# vpac_targetdb register map
Vendor: Texas Instruments
Registers are 32-bit, read-write, no defined reset value unless marked. A register's access mark holds for its fields unless they carry their own. Offsets are as the file gives them; [hi:lo] are bit positions; {n}, {i} and the like mark numbered series; 'fields as' and 'values as' point back to an identical list.

## VPAC (part 7 of 8) — Vision Pre-Processing Accelerator (VPAC)
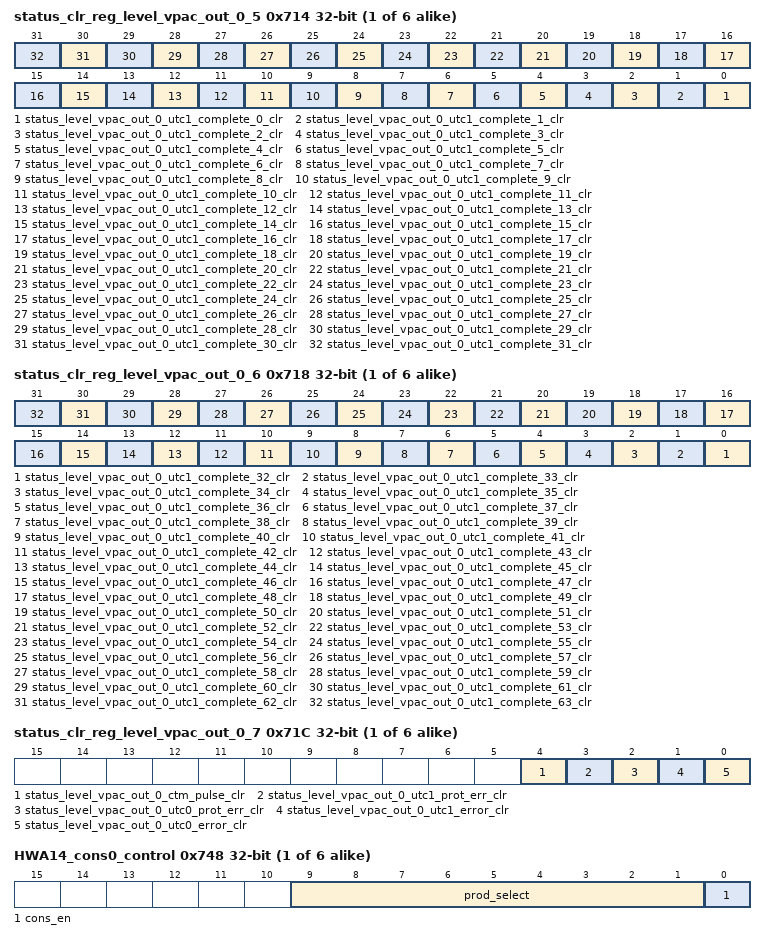
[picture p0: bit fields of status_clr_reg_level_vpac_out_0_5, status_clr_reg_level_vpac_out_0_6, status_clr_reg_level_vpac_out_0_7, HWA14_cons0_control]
{0x714+0x20*i} status_clr_reg_level_vpac_out_{i}_5 (i=0..5) — Status Clear Register {8i+5}
  [n] status_level_vpac_out_{i}_utc1_complete_{n}_clr (n=0..31) — Status ,write 1 to clear, for level_vpac_out_{i}_en_utc1_complete_{n}
{0x718+0x20*i} status_clr_reg_level_vpac_out_{i}_6 (i=0..5) — Status Clear Register {8i+6}
  [n-32] status_level_vpac_out_{i}_utc1_complete_{n}_clr (n=32..63) — Status ,write 1 to clear, for level_vpac_out_{i}_en_utc1_complete_{n}
{0x71C+0x20*i} status_clr_reg_level_vpac_out_{i}_7 (i=0..5) — Status Clear Register {8i+7}
  [4] status_level_vpac_out_{i}_ctm_pulse_clr — Status ,write 1 to clear, for level_vpac_out_{i}_en_ctm_pulse
  [3] status_level_vpac_out_{i}_utc1_prot_err_clr — Status ,write 1 to clear, for level_vpac_out_{i}_en_utc1_prot_err
  [2] status_level_vpac_out_{i}_utc0_prot_err_clr — Status ,write 1 to clear, for level_vpac_out_{i}_en_utc0_prot_err
  [1] status_level_vpac_out_{i}_utc1_error_clr — Status ,write 1 to clear, for level_vpac_out_{i}_en_utc1_error
  [0] status_level_vpac_out_{i}_utc0_error_clr — Status ,write 1 to clear, for level_vpac_out_{i}_en_utc0_error
{0x198+0x68*i} HWA{i}_cons0_control (i=14..19) — Controlling consumer socket 0 for HWA{i}
  [9:1] prod_select — producer select for HWA{i} cons socket 0
  [0] cons_en — '1' -> Consumer socket 0 enable , '0' Disable
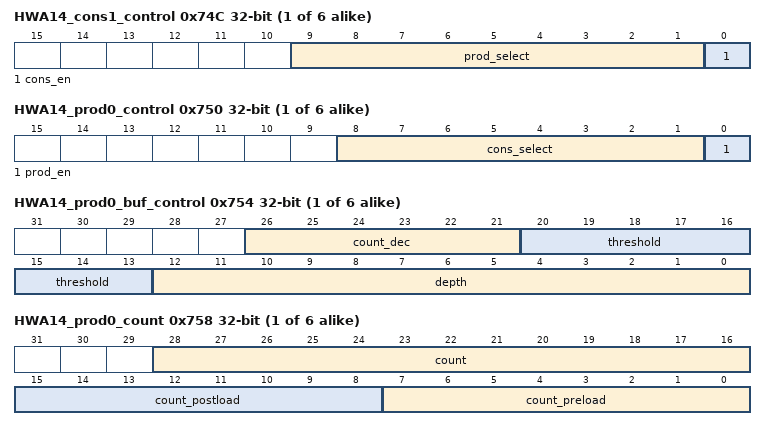
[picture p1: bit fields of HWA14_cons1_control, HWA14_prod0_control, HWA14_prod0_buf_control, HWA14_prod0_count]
{0x19C+0x68*i} HWA{i}_cons1_control (i=14..19) — Controlling consumer socket 1 for HWA{i}
  [9:1] prod_select — producer select for HWA{i} cons socket 1
  [0] cons_en — '1' -> Consumer socket 1 enable , '0' Disable
{0x1A0+0x68*i} HWA{i}_prod0_control (i=14..19) — Controlling producer socket0 for HWA{i}
  [8:1] cons_select — consumer select for HWA{i} prod socket 0. Used in decrementing count of producer buffer
  [0] prod_en — '1' -> Producer socket 0 enable , '0' Disable
{0x1A4+0x68*i} HWA{i}_prod0_buf_control (i=14..19) — Controlling producer socket0 buffer for HWA{i}
  [26:21] count_dec — Count decrement value for prod count
  [20:13] threshold — Count threshold to generate pend for consumer
  [12:0] depth — Maximum number of producer buffer count
{0x1A8+0x68*i} HWA{i}_prod0_count access per field (i=14..19) — Defining count values for pre/post load for generating pend by HWA{i} prod0
  [28:16] count ro — current count value
  [15:8] count_postload rw — count postload after producer max thread count reached
  [7:0] count_preload rw — count preload after scheduler start/init
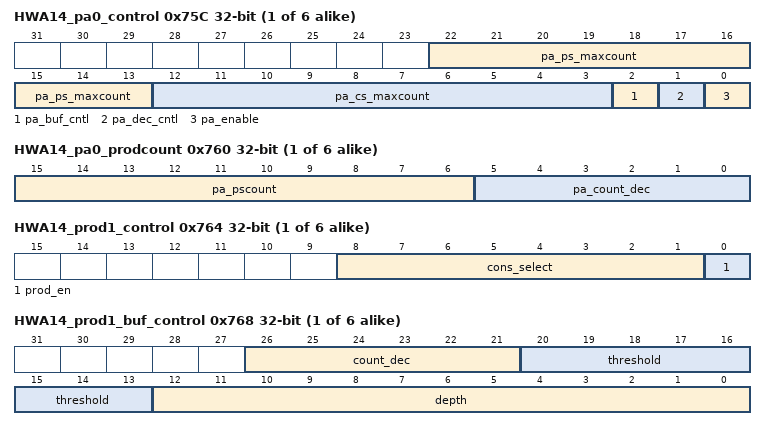
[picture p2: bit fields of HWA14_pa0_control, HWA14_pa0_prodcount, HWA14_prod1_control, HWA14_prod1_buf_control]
{0x1AC+0x68*i} HWA{i}_pa0_control (i=14..19) — control register to manage pattern adapter on HWA{i} prod socket0
  [22:13] pa_ps_maxcount — destination count for pattern adaptation (N), M --> N
  [12:3] pa_cs_maxcount — source count for pattern adaptation (M), M --> N
  [2] pa_buf_cntl — '1' -> Apply threshold, count_preload and count_postload on pattern adapter count (use this only when pa_enable='1') '0' -> Apply threshold, count_preload and count_postload on prod count (same behavior as if no pattern adapter. Note when pa_enable='1' and pa_buf_cntl='0' threshold is not used and ignored)
  [1] pa_dec_cntl — '1' -> post pattern adaptation, decrement ps count by count_dec , '0' -> post pattern adaptation, decrement ps count by pa_cs_maxcount
  [0] pa_enable — '1' -> pa enable, '0' -> disable
{0x1B0+0x68*i} HWA{i}_pa0_prodcount access per field (i=14..19) — count values for HWA{i} prod socket0
  [15:6] pa_pscount ro — current count value of pa prod count
  [5:0] pa_count_dec rw — Decrement count value of pa_prod_count after pattern adapter prod count reaches threshold
{0x1B4+0x68*i} HWA{i}_prod1_control (i=14..19) — Controlling producer socket1 for HWA{i}
  [8:1] cons_select — consumer select for HWA{i} prod socket 1. Used in decrementing count of producer buffer
  [0] prod_en — '1' -> Producer socket 0 enable , '0' Disable
{0x1B8+0x68*i} HWA{i}_prod1_buf_control (i=14..19) — Controlling producer socket1 buffer for HWA{i}
  fields as HWA14_prod0_buf_control
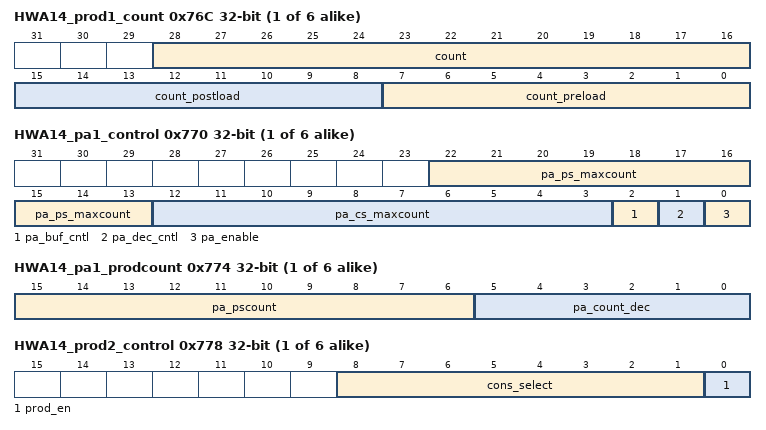
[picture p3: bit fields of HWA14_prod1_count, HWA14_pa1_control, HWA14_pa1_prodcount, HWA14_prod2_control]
{0x1BC+0x68*i} HWA{i}_prod1_count access per field (i=14..19) — Defining count values for pre/post load for generating pend by HWA{i} prod1
  fields as HWA14_prod0_count
{0x1C0+0x68*i} HWA{i}_pa1_control (i=14..19) — control register to manage pattern adapter on HWA{i} prod socket1
  fields as HWA14_pa0_control
{0x1C4+0x68*i} HWA{i}_pa1_prodcount access per field (i=14..19) — count values for HWA{i} prod socket1
  fields as HWA14_pa0_prodcount
{0x1C8+0x68*i} HWA{i}_prod2_control (i=14..19) — Controlling producer socket2 for HWA{i}
  [8:1] cons_select — consumer select for HWA{i} prod socket 2. Used in decrementing count of producer buffer
  [0] prod_en — '1' -> Producer socket 0 enable , '0' Disable
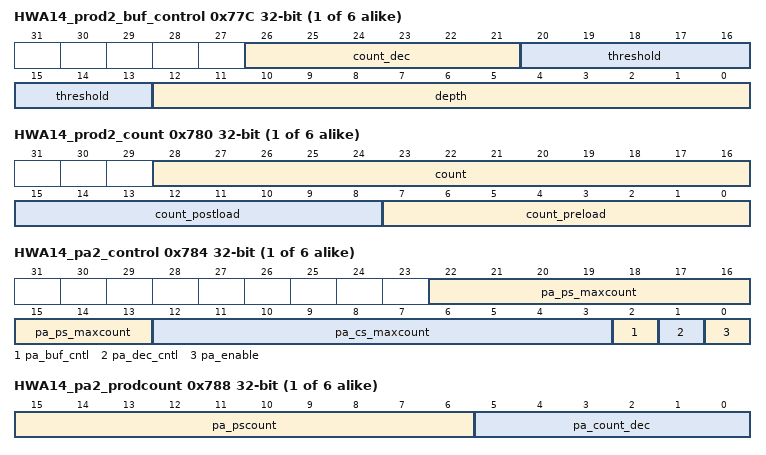
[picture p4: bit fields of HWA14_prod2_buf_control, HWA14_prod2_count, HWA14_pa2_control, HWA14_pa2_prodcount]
{0x1CC+0x68*i} HWA{i}_prod2_buf_control (i=14..19) — Controlling producer socket2 buffer for HWA{i}
  fields as HWA14_prod0_buf_control
{0x1D0+0x68*i} HWA{i}_prod2_count access per field (i=14..19) — Defining count values for pre/post load for generating pend by HWA{i} prod2
  fields as HWA14_prod0_count
{0x1D4+0x68*i} HWA{i}_pa2_control (i=14..19) — control register to manage pattern adapter on HWA{i} prod socket2
  fields as HWA14_pa0_control
{0x1D8+0x68*i} HWA{i}_pa2_prodcount access per field (i=14..19) — count values for HWA{i} prod socket2
  fields as HWA14_pa0_prodcount
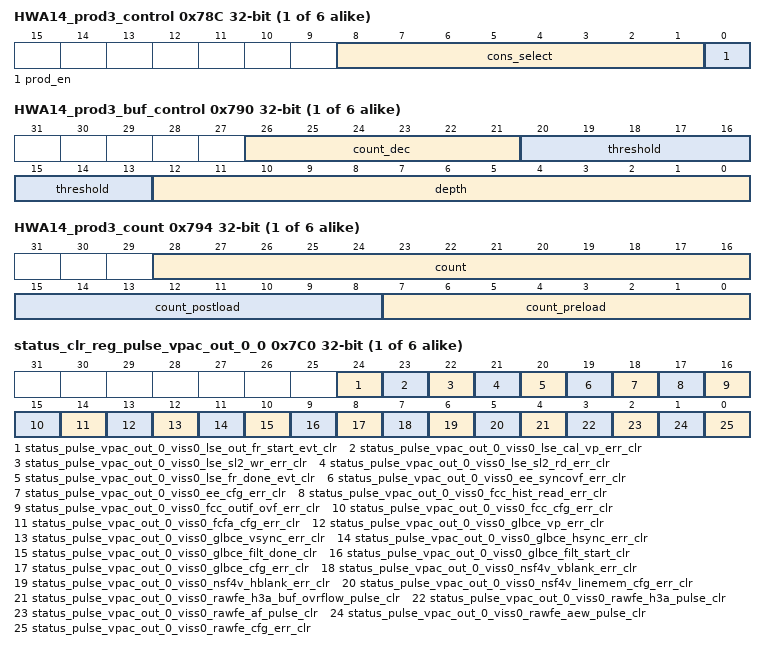
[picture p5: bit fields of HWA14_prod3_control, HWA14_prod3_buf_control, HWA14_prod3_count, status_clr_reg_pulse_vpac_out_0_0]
{0x1DC+0x68*i} HWA{i}_prod3_control (i=14..19) — Controlling producer socket3 for HWA{i}
  [8:1] cons_select — consumer select for HWA{i} prod socket 3. Used in decrementing count of producer buffer
  [0] prod_en — '1' -> Producer socket 0 enable , '0' Disable
{0x1E0+0x68*i} HWA{i}_prod3_buf_control (i=14..19) — Controlling producer socket3 buffer for HWA{i}
  fields as HWA14_prod0_buf_control
{0x1E4+0x68*i} HWA{i}_prod3_count access per field (i=14..19) — Defining count values for pre/post load for generating pend by HWA{i} prod3
  fields as HWA14_prod0_count
{0x7C0+0x20*i} status_clr_reg_pulse_vpac_out_{i}_0 (i=0..5) — Status Clear Register {8i+48}
  [24] status_pulse_vpac_out_{i}_viss0_lse_out_fr_start_evt_clr — Status ,write 1 to clear, for pulse_vpac_out_{i}_en_viss0_lse_out_fr_start_evt
  [23] status_pulse_vpac_out_{i}_viss0_lse_cal_vp_err_clr — Status ,write 1 to clear, for pulse_vpac_out_{i}_en_viss0_lse_cal_vp_err
  [22] status_pulse_vpac_out_{i}_viss0_lse_sl2_wr_err_clr — Status ,write 1 to clear, for pulse_vpac_out_{i}_en_viss0_lse_sl2_wr_err
  [21] status_pulse_vpac_out_{i}_viss0_lse_sl2_rd_err_clr — Status ,write 1 to clear, for pulse_vpac_out_{i}_en_viss0_lse_sl2_rd_err
  [20] status_pulse_vpac_out_{i}_viss0_lse_fr_done_evt_clr — Status ,write 1 to clear, for pulse_vpac_out_{i}_en_viss0_lse_fr_done_evt
  [19] status_pulse_vpac_out_{i}_viss0_ee_syncovf_err_clr — Status ,write 1 to clear, for pulse_vpac_out_{i}_en_viss0_ee_syncovf_err
  [18] status_pulse_vpac_out_{i}_viss0_ee_cfg_err_clr — Status ,write 1 to clear, for pulse_vpac_out_{i}_en_viss0_ee_cfg_err
  [17] status_pulse_vpac_out_{i}_viss0_fcc_hist_read_err_clr — Status ,write 1 to clear, for pulse_vpac_out_{i}_en_viss0_fcc_hist_read_err
  [16] status_pulse_vpac_out_{i}_viss0_fcc_outif_ovf_err_clr — Status ,write 1 to clear, for pulse_vpac_out_{i}_en_viss0_fcc_outif_ovf_err
  [15] status_pulse_vpac_out_{i}_viss0_fcc_cfg_err_clr — Status ,write 1 to clear, for pulse_vpac_out_{i}_en_viss0_fcc_cfg_err
  [14] status_pulse_vpac_out_{i}_viss0_fcfa_cfg_err_clr — Status ,write 1 to clear, for pulse_vpac_out_{i}_en_viss0_fcfa_cfg_err
  [13] status_pulse_vpac_out_{i}_viss0_glbce_vp_err_clr — Status ,write 1 to clear, for pulse_vpac_out_{i}_en_viss0_glbce_vp_err
  [12] status_pulse_vpac_out_{i}_viss0_glbce_vsync_err_clr — Status ,write 1 to clear, for pulse_vpac_out_{i}_en_viss0_glbce_vsync_err
  [11] status_pulse_vpac_out_{i}_viss0_glbce_hsync_err_clr — Status ,write 1 to clear, for pulse_vpac_out_{i}_en_viss0_glbce_hsync_err
  [10] status_pulse_vpac_out_{i}_viss0_glbce_filt_done_clr — Status ,write 1 to clear, for pulse_vpac_out_{i}_en_viss0_glbce_filt_done
  [9] status_pulse_vpac_out_{i}_viss0_glbce_filt_start_clr — Status ,write 1 to clear, for pulse_vpac_out_{i}_en_viss0_glbce_filt_start
  [8] status_pulse_vpac_out_{i}_viss0_glbce_cfg_err_clr — Status ,write 1 to clear, for pulse_vpac_out_{i}_en_viss0_glbce_cfg_err
  [7] status_pulse_vpac_out_{i}_viss0_nsf4v_vblank_err_clr — Status ,write 1 to clear, for pulse_vpac_out_{i}_en_viss0_nsf4v_vblank_err
  [6] status_pulse_vpac_out_{i}_viss0_nsf4v_hblank_err_clr — Status ,write 1 to clear, for pulse_vpac_out_{i}_en_viss0_nsf4v_hblank_err
  [5] status_pulse_vpac_out_{i}_viss0_nsf4v_linemem_cfg_err_clr — Status ,write 1 to clear, for pulse_vpac_out_{i}_en_viss0_nsf4v_linemem_cfg_err
  [4] status_pulse_vpac_out_{i}_viss0_rawfe_h3a_buf_ovrflow_pulse_clr — Status ,write 1 to clear, for pulse_vpac_out_{i}_en_viss0_rawfe_h3a_buf_ovrflow_pulse
  [3] status_pulse_vpac_out_{i}_viss0_rawfe_h3a_pulse_clr — Status ,write 1 to clear, for pulse_vpac_out_{i}_en_viss0_rawfe_h3a_pulse
  [2] status_pulse_vpac_out_{i}_viss0_rawfe_af_pulse_clr — Status ,write 1 to clear, for pulse_vpac_out_{i}_en_viss0_rawfe_af_pulse
  [1] status_pulse_vpac_out_{i}_viss0_rawfe_aew_pulse_clr — Status ,write 1 to clear, for pulse_vpac_out_{i}_en_viss0_rawfe_aew_pulse
  [0] status_pulse_vpac_out_{i}_viss0_rawfe_cfg_err_clr — Status ,write 1 to clear, for pulse_vpac_out_{i}_en_viss0_rawfe_cfg_err
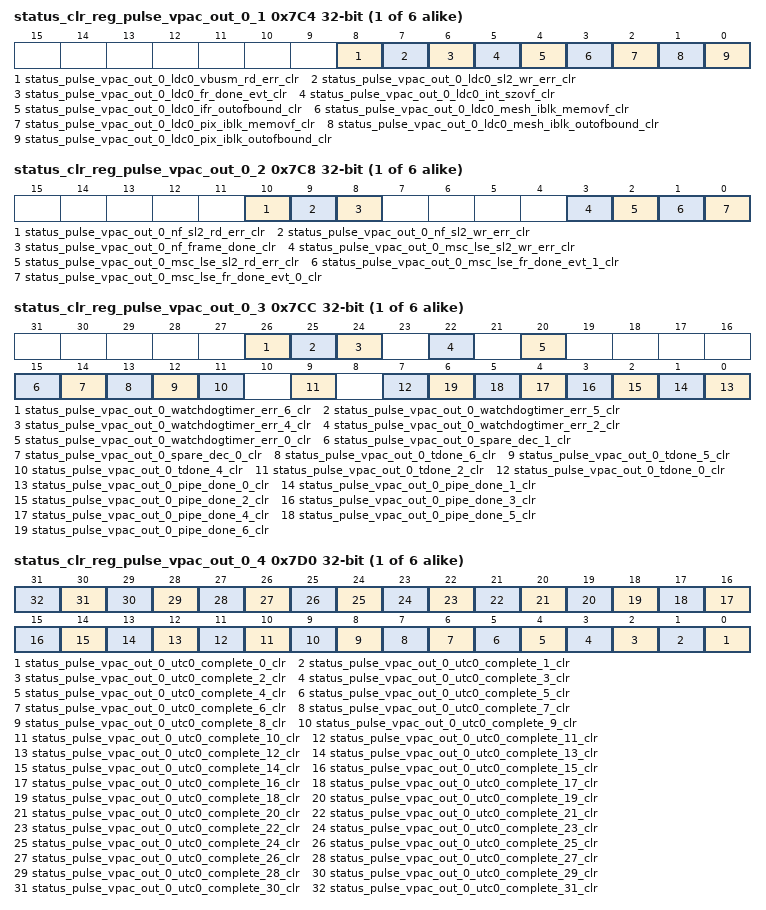
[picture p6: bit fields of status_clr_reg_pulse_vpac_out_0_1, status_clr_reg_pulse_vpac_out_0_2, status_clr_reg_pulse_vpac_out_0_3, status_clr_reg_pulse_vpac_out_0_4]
{0x7C4+0x20*i} status_clr_reg_pulse_vpac_out_{i}_1 (i=0..5) — Status Clear Register {8i+49}
  [8] status_pulse_vpac_out_{i}_ldc0_vbusm_rd_err_clr — Status ,write 1 to clear, for pulse_vpac_out_{i}_en_ldc0_vbusm_rd_err
  [7] status_pulse_vpac_out_{i}_ldc0_sl2_wr_err_clr — Status ,write 1 to clear, for pulse_vpac_out_{i}_en_ldc0_sl2_wr_err
  [6] status_pulse_vpac_out_{i}_ldc0_fr_done_evt_clr — Status ,write 1 to clear, for pulse_vpac_out_{i}_en_ldc0_fr_done_evt
  [5] status_pulse_vpac_out_{i}_ldc0_int_szovf_clr — Status ,write 1 to clear, for pulse_vpac_out_{i}_en_ldc0_int_szovf
  [4] status_pulse_vpac_out_{i}_ldc0_ifr_outofbound_clr — Status ,write 1 to clear, for pulse_vpac_out_{i}_en_ldc0_ifr_outofbound
  [3] status_pulse_vpac_out_{i}_ldc0_mesh_iblk_memovf_clr — Status ,write 1 to clear, for pulse_vpac_out_{i}_en_ldc0_mesh_iblk_memovf
  [2] status_pulse_vpac_out_{i}_ldc0_pix_iblk_memovf_clr — Status ,write 1 to clear, for pulse_vpac_out_{i}_en_ldc0_pix_iblk_memovf
  [1] status_pulse_vpac_out_{i}_ldc0_mesh_iblk_outofbound_clr — Status ,write 1 to clear, for pulse_vpac_out_{i}_en_ldc0_mesh_iblk_outofbound
  [0] status_pulse_vpac_out_{i}_ldc0_pix_iblk_outofbound_clr — Status ,write 1 to clear, for pulse_vpac_out_{i}_en_ldc0_pix_iblk_outofbound
{0x7C8+0x20*i} status_clr_reg_pulse_vpac_out_{i}_2 (i=0..5) — Status Clear Register {8i+50}
  [10] status_pulse_vpac_out_{i}_nf_sl2_rd_err_clr — Status ,write 1 to clear, for pulse_vpac_out_{i}_en_nf_sl2_rd_err
  [9] status_pulse_vpac_out_{i}_nf_sl2_wr_err_clr — Status ,write 1 to clear, for pulse_vpac_out_{i}_en_nf_sl2_wr_err
  [8] status_pulse_vpac_out_{i}_nf_frame_done_clr — Status ,write 1 to clear, for pulse_vpac_out_{i}_en_nf_frame_done
  [3] status_pulse_vpac_out_{i}_msc_lse_sl2_wr_err_clr — Status ,write 1 to clear, for pulse_vpac_out_{i}_en_msc_lse_sl2_wr_err
  [2] status_pulse_vpac_out_{i}_msc_lse_sl2_rd_err_clr — Status ,write 1 to clear, for pulse_vpac_out_{i}_en_msc_lse_sl2_rd_err
  [1] status_pulse_vpac_out_{i}_msc_lse_fr_done_evt_1_clr — Status ,write 1 to clear, for pulse_vpac_out_{i}_en_msc_lse_fr_done_evt_1
  [0] status_pulse_vpac_out_{i}_msc_lse_fr_done_evt_0_clr — Status ,write 1 to clear, for pulse_vpac_out_{i}_en_msc_lse_fr_done_evt_0
{0x7CC+0x20*i} status_clr_reg_pulse_vpac_out_{i}_3 (i=0..5) — Status Clear Register {8i+51}
  [26] status_pulse_vpac_out_{i}_watchdogtimer_err_6_clr — Status ,write 1 to clear, for pulse_vpac_out_{i}_en_watchdogtimer_err_6
  [25] status_pulse_vpac_out_{i}_watchdogtimer_err_5_clr — Status ,write 1 to clear, for pulse_vpac_out_{i}_en_watchdogtimer_err_5
  [24] status_pulse_vpac_out_{i}_watchdogtimer_err_4_clr — Status ,write 1 to clear, for pulse_vpac_out_{i}_en_watchdogtimer_err_4
  [22] status_pulse_vpac_out_{i}_watchdogtimer_err_2_clr — Status ,write 1 to clear, for pulse_vpac_out_{i}_en_watchdogtimer_err_2
  [20] status_pulse_vpac_out_{i}_watchdogtimer_err_0_clr — Status ,write 1 to clear, for pulse_vpac_out_{i}_en_watchdogtimer_err_0
  [15] status_pulse_vpac_out_{i}_spare_dec_1_clr — Status ,write 1 to clear, for pulse_vpac_out_{i}_en_spare_dec_1
  [14] status_pulse_vpac_out_{i}_spare_dec_0_clr — Status ,write 1 to clear, for pulse_vpac_out_{i}_en_spare_dec_0
  [13] status_pulse_vpac_out_{i}_tdone_6_clr — Status ,write 1 to clear, for pulse_vpac_out_{i}_en_tdone_6
  [12] status_pulse_vpac_out_{i}_tdone_5_clr — Status ,write 1 to clear, for pulse_vpac_out_{i}_en_tdone_5
  [11] status_pulse_vpac_out_{i}_tdone_4_clr — Status ,write 1 to clear, for pulse_vpac_out_{i}_en_tdone_4
  [9] status_pulse_vpac_out_{i}_tdone_2_clr — Status ,write 1 to clear, for pulse_vpac_out_{i}_en_tdone_2
  [7] status_pulse_vpac_out_{i}_tdone_0_clr — Status ,write 1 to clear, for pulse_vpac_out_{i}_en_tdone_0
  [n] status_pulse_vpac_out_{i}_pipe_done_{n}_clr (n=0..6) — Status ,write 1 to clear, for pulse_vpac_out_{i}_en_pipe_done_{n}
{0x7D0+0x20*i} status_clr_reg_pulse_vpac_out_{i}_4 (i=0..5) — Status Clear Register {8i+52}
  [n] status_pulse_vpac_out_{i}_utc0_complete_{n}_clr (n=0..31) — Status ,write 1 to clear, for pulse_vpac_out_{i}_en_utc0_complete_{n}
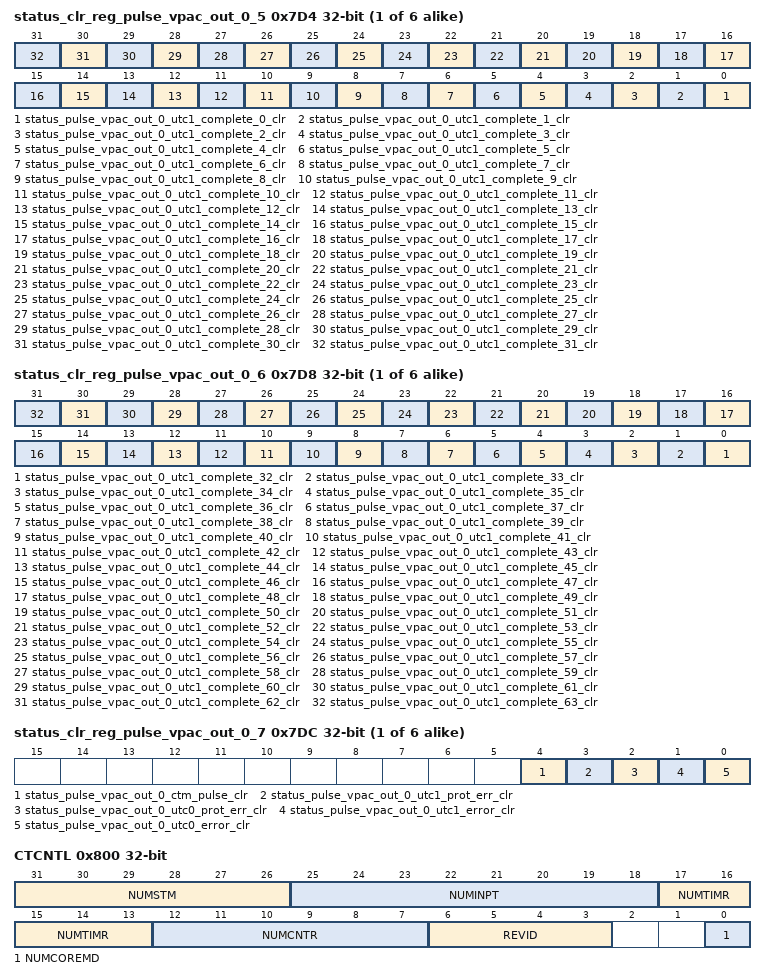
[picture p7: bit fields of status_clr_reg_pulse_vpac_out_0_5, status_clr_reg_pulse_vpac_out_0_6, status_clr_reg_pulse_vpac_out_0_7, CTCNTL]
{0x7D4+0x20*i} status_clr_reg_pulse_vpac_out_{i}_5 (i=0..5) — Status Clear Register {8i+53}
  [n] status_pulse_vpac_out_{i}_utc1_complete_{n}_clr (n=0..31) — Status ,write 1 to clear, for pulse_vpac_out_{i}_en_utc1_complete_{n}
{0x7D8+0x20*i} status_clr_reg_pulse_vpac_out_{i}_6 (i=0..5) — Status Clear Register {8i+54}
  [n-32] status_pulse_vpac_out_{i}_utc1_complete_{n}_clr (n=32..63) — Status ,write 1 to clear, for pulse_vpac_out_{i}_en_utc1_complete_{n}
{0x7DC+0x20*i} status_clr_reg_pulse_vpac_out_{i}_7 (i=0..5) — Status Clear Register {8i+55}
  [4] status_pulse_vpac_out_{i}_ctm_pulse_clr — Status ,write 1 to clear, for pulse_vpac_out_{i}_en_ctm_pulse
  [3] status_pulse_vpac_out_{i}_utc1_prot_err_clr — Status ,write 1 to clear, for pulse_vpac_out_{i}_en_utc1_prot_err
  [2] status_pulse_vpac_out_{i}_utc0_prot_err_clr — Status ,write 1 to clear, for pulse_vpac_out_{i}_en_utc0_prot_err
  [1] status_pulse_vpac_out_{i}_utc1_error_clr — Status ,write 1 to clear, for pulse_vpac_out_{i}_en_utc1_error
  [0] status_pulse_vpac_out_{i}_utc0_error_clr — Status ,write 1 to clear, for pulse_vpac_out_{i}_en_utc0_error
0x800 CTCNTL ro — Counter Timer Control
  [31:26] NUMSTM — Number of counters that can export via STM
  [25:18] NUMINPT — Number of event input signals
  [17:13] NUMTIMR — Number of timers in the module
  [12:7] NUMCNTR — Number of counters in the module
  [6:3] REVID — Revision ID of CTSET
  [0] NUMCOREMD — Indicated the number of mode bus interfaces, 0 is 2 CPU buses, 1 is 4 buses
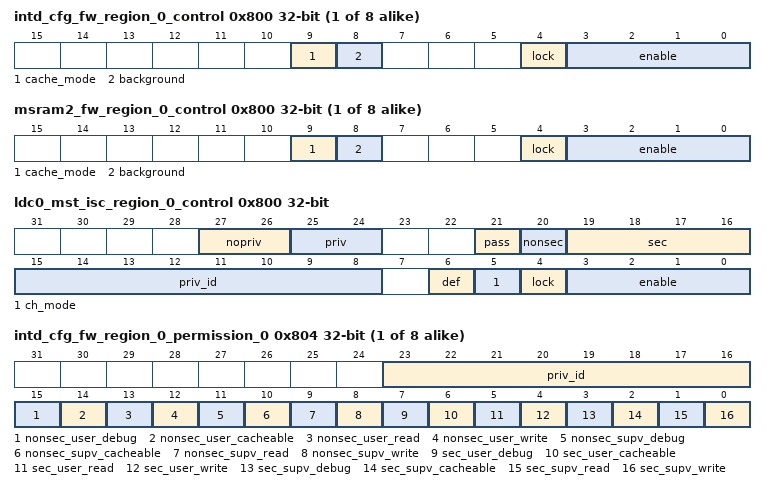
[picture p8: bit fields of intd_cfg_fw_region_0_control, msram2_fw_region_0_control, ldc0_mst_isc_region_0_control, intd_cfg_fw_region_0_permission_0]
{0x800+0x20*i} intd_cfg_fw_region_{i}_control (i=0..7) — The FW Region {i} Control Register defines the control fields for the slave cp_intd.intd_cfg region {i} firewall.
  [9] cache_mode — Cache mode for region. Set to 1 to check cache permissions. Set to 0 to ignore cache permissions.
  [8] background — Background enable for region. There can be 1 backgroun region per FW and foreground regions can have overlapping addresses only with the background region.
  [4] lock — Lock region. Once set region values cannot be modified.
  [3:0] enable — Enable region. A value of 0xA enables, others disable.
{0x800+0x20*i} msram2_fw_region_{i}_control (i=0..7) — The FW Region {i} Control Register defines the control fields for the slave ksbus_msram2.slv region {i} firewall.
  fields as intd_cfg_fw_region_0_control
0x800 ldc0_mst_isc_region_0_control access per field — The ISC Region 0 Control Register defines the control fields for the master .ldc0_mst region 0 ISC.
  [27:26] nopriv rw — Clear output priv attribute. If each bit is set then the outgoing priv bit is cleared.
  [25:24] priv rw — Set outgoing priv attribute. If each bit is set then the outgoing priv bit is set.
  [21] pass rw — No privID replacement, pass through value.
  [20] nonsec rw — Make outgoing non-secure.
  [19:16] sec rw — Make outgoing secure. A value of 0xA enables, others disable.
  [15:8] priv_id rw
  [6] def ro — Default region indication. The default region is used when all other regions do not match.
  [5] ch_mode rw — Enable channel mode to match region to a chanid value. Otherwise use address mode to match region to an address range.
  [4] lock rw — Lock region. Once set the region values cannot be modified.
  [3:0] enable rw — Enable region. A value of 0xA enables, others disable.
0x804 CTNUMDBG ro — Counter Timer Number Debug Event Register
  [2:0] NUMEVT — Number of input selectors for debug events
{0x804+0x20*i} intd_cfg_fw_region_{i}_permission_0 (i=0..7) — The FW Region {i} Permission 0 Register defines the permissions for the slave cp_intd.intd_cfg region {i} firewall.
  [23:16] priv_id — Allowed privid.
  [15] nonsec_user_debug — Non-secure user debug allowed.
  [14] nonsec_user_cacheable — Non-secure user cacheable allowed.
  [13] nonsec_user_read — Non-secure user read allowed.
  [12] nonsec_user_write — Non-secure user write allowed.
  [11] nonsec_supv_debug — Non-secure supervisor debug allowed.
  [10] nonsec_supv_cacheable — Non-secure supervisor cacheable allowed.
  [9] nonsec_supv_read — Non-secure supervisor read allowed.
  [8] nonsec_supv_write — Non-secure supervisor write allowed.
  [7] sec_user_debug — Secure user debug allowed.
  [6] sec_user_cacheable — Secure user cacheable allowed.
  [5] sec_user_read — Secure user read allowed.
  [4] sec_user_write — Secure user write allowed.
  [3] sec_supv_debug — Secure supervisor debug allowed.
  [2] sec_supv_cacheable — Secure supervisor cacheable allowed.
  [1] sec_supv_read — Secure supervisor read allowed.
  [0] sec_supv_write — Secure supervisor write allowed.
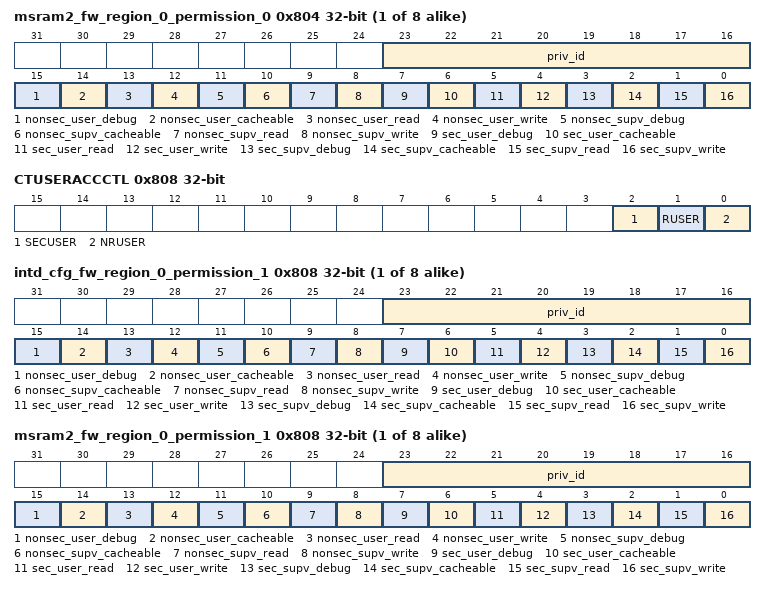
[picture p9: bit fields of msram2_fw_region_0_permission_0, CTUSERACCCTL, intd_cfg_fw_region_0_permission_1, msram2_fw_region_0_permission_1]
{0x804+0x20*i} msram2_fw_region_{i}_permission_0 (i=0..7) — The FW Region {i} Permission 0 Register defines the permissions for the slave ksbus_msram2.slv region {i} firewall.
  fields as intd_cfg_fw_region_0_permission_0
0x808 CTUSERACCCTL access per field — Counter Timer User Access Control, can only be written in priviledged mode
  [2] SECUSER rw — Counter functions while system is in Secure-User mode
  [1] RUSER rw — Counter functions while system is in Root-User mode
  [0] NRUSER rw — Counter functions while system is in in Non-Root-User mode
{0x808+0x20*i} intd_cfg_fw_region_{i}_permission_1 (i=0..7) — The FW Region {i} Permission 1 Register defines the permissions for the slave cp_intd.intd_cfg region {i} firewall.
  fields as intd_cfg_fw_region_0_permission_0
{0x808+0x20*i} msram2_fw_region_{i}_permission_1 (i=0..7) — The FW Region {i} Permission 1 Register defines the permissions for the slave ksbus_msram2.slv region {i} firewall.
  fields as intd_cfg_fw_region_0_permission_0
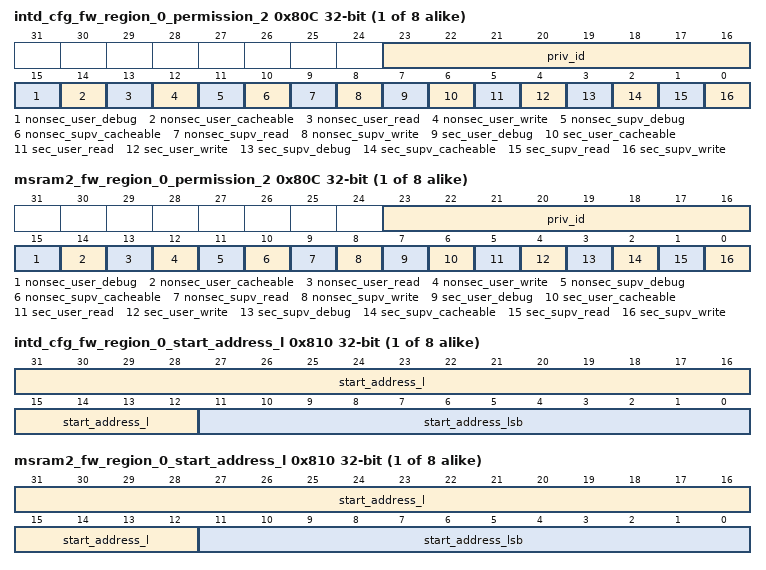
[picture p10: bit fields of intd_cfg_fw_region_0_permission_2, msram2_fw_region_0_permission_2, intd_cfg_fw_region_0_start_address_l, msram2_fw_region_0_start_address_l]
{0x80C+0x20*i} intd_cfg_fw_region_{i}_permission_2 (i=0..7) — The FW Region {i} Permission 2 Register defines the permissions for the slave cp_intd.intd_cfg region {i} firewall.
  fields as intd_cfg_fw_region_0_permission_0
{0x80C+0x20*i} msram2_fw_region_{i}_permission_2 (i=0..7) — The FW Region {i} Permission 2 Register defines the permissions for the slave ksbus_msram2.slv region {i} firewall.
  fields as intd_cfg_fw_region_0_permission_0
{0x810+0x20*i} intd_cfg_fw_region_{i}_start_address_l access per field (i=0..7) — The FW Region {i} Start Address Low Register defines the start address bits 31 to 0 for the slave cp_intd.intd_cfg region {i} firewall.
  [31:12] start_address_l rw — Start address bits 31 to 12. Lowest 12 bits are forced to 0 as address must be 4KB aligned.
  [11:0] start_address_lsb ro — Start address bits 11 to 0 are forced to 0 as address must be 4KB aligned.
{0x810+0x20*i} msram2_fw_region_{i}_start_address_l access per field (i=0..7) — The FW Region {i} Start Address Low Register defines the start address bits 31 to 0 for the slave ksbus_msram2.slv region {i} firewall.
  fields as intd_cfg_fw_region_0_start_address_l
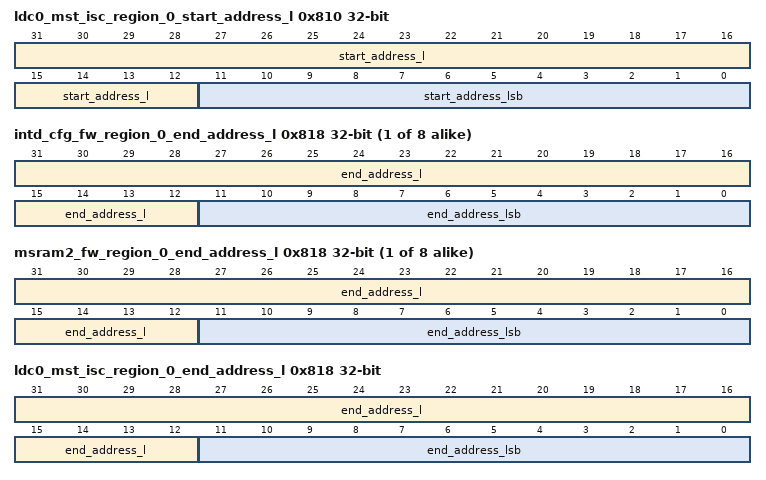
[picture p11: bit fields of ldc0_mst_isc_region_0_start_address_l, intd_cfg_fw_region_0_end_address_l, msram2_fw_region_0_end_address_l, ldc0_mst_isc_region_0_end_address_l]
0x810 ldc0_mst_isc_region_0_start_address_l — The ISC Region 0 Start Address Low Register defines the start address bits 31 to 0 for the master .ldc0_mst region 0 ISC.
  [31:12] start_address_l — Start address bits 31 to 12.
  [11:0] start_address_lsb — Start address bits 11 to 0 must be 0 as address must be 4KB aligned in address mode. Can also be channel number in channel mode.
{0x814+0x20*i} intd_cfg_fw_region_{i}_start_address_h (i=0..7) — The FW Region {i} Start Address High Register defines the start address bits 47 to 32 for the slave cp_intd.intd_cfg region {i} firewall.
  [15:0] start_address_h — Start address bits 47 to 32.
{0x814+0x20*i} msram2_fw_region_{i}_start_address_h (i=0..7) — The FW Region {i} Start Address High Register defines the start address bits 47 to 32 for the slave ksbus_msram2.slv region {i} firewall.
  [15:0] start_address_h — Start address bits 47 to 32.
0x814 ldc0_mst_isc_region_0_start_address_h — The ISC Region 0 Start Address High Register defines the start address bits 47 to 32 for the master .ldc0_mst region 0 ISC.
  [15:0] start_address_h — Start address bits 47 to 32.
{0x818+0x20*i} intd_cfg_fw_region_{i}_end_address_l access per field (i=0..7) — The FW Region {i} End Address Low Register defines the end address bits 31 to 0 to include for the slave cp_intd.intd_cfg region {i} firewall.
  [31:12] end_address_l rw — End address bits 31 to 12 to include in the match. Lowest 12 bits are forced to 1s as address must be 4KB aligned.
  [11:0] end_address_lsb ro — End address bits 11 to 0 are forced to 1s as address must be 4KB aligned minus 1.
{0x818+0x20*i} msram2_fw_region_{i}_end_address_l access per field (i=0..7) — The FW Region {i} End Address Low Register defines the end address bits 31 to 0 to include for the slave ksbus_msram2.slv region {i} firewall.
  fields as intd_cfg_fw_region_0_end_address_l
0x818 ldc0_mst_isc_region_0_end_address_l access per field — The ISC Region 0 End Address Low Register defines the end included address bits 31 to 0 for the master .ldc0_mst region 0 ISC.
  [31:12] end_address_l rw — End address bits 31 to 12 to include in the match.
  [11:0] end_address_lsb ro — End address bits 11 to 0 are forced to Fs as address must be 4KB aligned.
{0x81C+0x20*i} intd_cfg_fw_region_{i}_end_address_h (i=0..7) — The FW Region {i} End Address High Register defines the end address bits 47 to 32 to include for the slave cp_intd.intd_cfg region {i} firewall.
  [15:0] end_address_h — End address bits 47 to 32 to include in the match.
{0x81C+0x20*i} msram2_fw_region_{i}_end_address_h (i=0..7) — The FW Region {i} End Address High Register defines the end address bits 47 to 32 to include for the slave ksbus_msram2.slv region {i} firewall.
  fields as intd_cfg_fw_region_0_end_address_h
0x81C ldc0_mst_isc_region_0_end_address_h — The ISC Region 0 End Address High Register defines the end address bits 47 to 32 for the master .ldc0_mst region 0 ISC.
  [15:0] end_address_h — End address bits 47 to 32.
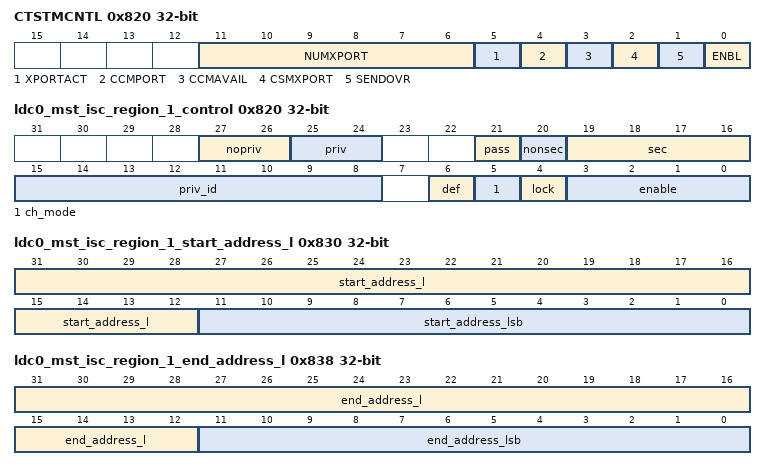
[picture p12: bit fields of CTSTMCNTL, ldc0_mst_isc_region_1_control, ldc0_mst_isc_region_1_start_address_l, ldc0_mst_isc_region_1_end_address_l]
0x820 CTSTMCNTL access per field — Counter Timer STM Control register
  [11:6] NUMXPORT ro — The total number of counters designated for export
  [5] XPORTACT ro — Indicates if a frame is currently being written to the STM.
  [4] CCMPORT rw — SW control of CCM message export
  [3] CCMAVAIL rw — CTSET supports CCM export
  [2] CSMXPORT rw — SW control of CSM message export
  [1] SENDOVR rw — Send overflow data in CSM frame
  [0] ENBL rw — CTSET STM global enable for counter/timer messages
0x820 ldc0_mst_isc_region_1_control access per field — The ISC Region 1 Control Register defines the control fields for the master .ldc0_mst region 1 ISC.
  fields as ldc0_mst_isc_region_0_control
0x824 CTSTMMSTID access per field — Counter Timer STM Master ID register
  [7:0] MASTID rw — HW Master ID for System Event module
0x828 CTSTMINTVL access per field — Counter Timer STM Interval Register
  [14:0] INTERVAL rw — Counter Timer Periodic export interval
0x82C CTSTMSEL0 — Counter Timer STM Counter Select Register 0. This Selects Counter 0 to 31
  [31:0] COUNTSEL — The individual bit is this field indicate whether the corresponding counter value is included in the CSM message generated via the STM interface
0x830 CTSTMSEL1 — Counter Timer STM Counter Select Register 1. This Selects Counter 32 to 63
  fields as CTSTMSEL0
0x830 ldc0_mst_isc_region_1_start_address_l — The ISC Region 1 Start Address Low Register defines the start address bits 31 to 0 for the master .ldc0_mst region 1 ISC.
  fields as ldc0_mst_isc_region_0_start_address_l
0x834 ldc0_mst_isc_region_1_start_address_h — The ISC Region 1 Start Address High Register defines the start address bits 47 to 32 for the master .ldc0_mst region 1 ISC.
  [15:0] start_address_h — Start address bits 47 to 32.
0x838 ldc0_mst_isc_region_1_end_address_l access per field — The ISC Region 1 End Address Low Register defines the end included address bits 31 to 0 for the master .ldc0_mst region 1 ISC.
  fields as ldc0_mst_isc_region_0_end_address_l
0x83C ldc0_mst_isc_region_1_end_address_h — The ISC Region 1 End Address High Register defines the end address bits 47 to 32 for the master .ldc0_mst region 1 ISC.
  [15:0] end_address_h — End address bits 47 to 32.
{0x840+4i} CTINTVLR{i} (i=0..15) — These registers contain the interval match value for the corresponding timers in the CTSET. TINTVLRn are available based on number of timers instantiated.
  [31:0] INTERVAL — Interval match value for the timers in the CTSET
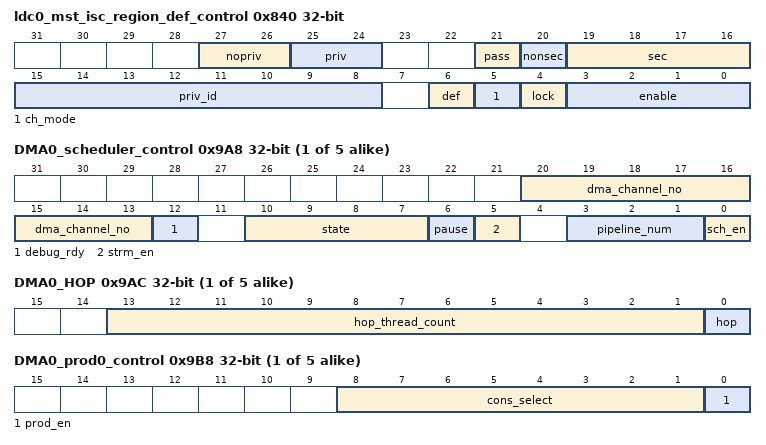
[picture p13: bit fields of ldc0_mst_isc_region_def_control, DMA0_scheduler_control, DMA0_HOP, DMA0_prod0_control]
0x840 ldc0_mst_isc_region_def_control access per field — The ISC Default Region Control Register defines the control fields for the master .ldc0_mst region 2 ISC.
  [27:26] nopriv rw — Clear output priv attribute. If each bit is set then the outgoing priv bit is cleared.
  [25:24] priv rw — Set outgoing priv attribute. If each bit is set then the outgoing priv bit is set.
  [21] pass rw — No privID replacement, pass through value.
  [20] nonsec rw — Make outgoing non-secure.
  [19:16] sec rw — Make outgoing secure. A value of 0xA enables, others disable.
  [15:8] priv_id rw
  [6] def ro — Default region indication. The default region is used when all other regions do not match.
  [5] ch_mode ro — Enable channel mode to match region to a chanid value. Otherwise use address mode to match region to an address range.
  [4] lock rw — Lock region. Once set, the region values cannot be modified.
  [3:0] enable ro — Enable region. A value of 0xA enables, others disable.
0x8A0 CTDBGSGL0 access per field — Timer Interval Register 0. Interval match value for timer 0 in CTSET Timer Interval Register 1. Interval match value for timer 1 in CTSET Timer Interval Register 2. Interval match value for timer 2 in CTSET Timer Interval Register 3. Interval match value for timer 3 in CTSET Timer Interval Register 4. Interval match value for timer 4 in CTSET Timer Interval Register 5. Interval match value for timer 5 in CTSET Timer Interval Register 6. Interval match value for timer 6 in CTSET Timer Interval Register 7. Interval match value for timer 7 in CTSET Timer Interval Register 8. Interval match value for timer 8 in CTSET Timer Interval Register 9. Interval match value for timer 9 in CTSET Timer Interval Register 10. Interval match value for timer 10 in CTSET Timer Interval Register 11. Interval match value for timer 11 in CTSET Timer Interval Register 12. Interval match value for timer 12 in CTSET Timer Interval Register 13. Interval match value for timer 13 in CTSET Timer Interval Register 14. Interval match value for timer 14 in CTSET Timer Interval Register 15. Interval match value for timer 15 in CTSET Counter Timer Debug Event Register 0
  [7:0] INPSEL rw — Counter Timer input selection
{0x8A0+4i} CTDBGSGL{i} access per field (i=1..4) — Counter Timer Debug Event Register {i}
  [7:0] INPSEL rw — Counter Timer input selection
0x8B4 CTDBGSGL5 access per field — Counter Timer Debug Event Register5
  [7:0] INPSEL rw — Counter Timer input selection
0x8B8 CTDBGSGL6 access per field — Counter Timer Debug Event Register 6
  [7:0] INPSEL rw — Counter Timer input selection
0x8BC CTDBGSGL7 access per field — Counter Timer Debug Event Register 7
  [7:0] INPSEL rw — Counter Timer input selection
{0x9A8+0x1C*i} DMA{i}_scheduler_control access per field (i=0..4) — Scheduler Control Register
  [20:13] dma_channel_no rw — DMA channel number for thread scheduler for DMA{i}
  [12] debug_rdy rw — '0' -> DMA{i} Scheduler resources must not be read during halted state. '1'-> DMA{i} Scheduler resources are readable during halted state
  [10:7] state ro — Current state of DMA{i} Scheduler
  [6] pause rw — '1' -> pause/suspend scheduler , '0' -> resume scheduler
  [5] strm_en rw — '1' -> Streaming input enable, '0' No streaming input
  [3:1] pipeline_num rw — Pipeline Number of DMA{i} Scheduler
  [0] sch_en rw — scheduler enable; write '1' to enable scheduler
{0x9AC+0x1C*i} DMA{i}_HOP (i=0..4) — Scheduler HOP Control Register. Help in detecting eop within scheduler. Once configured, it counts task/channel starts and stops issuing further starts. Specifically useful for Head of pipe dma scheduler .
  [13:1] hop_thread_count — Number of Task count for Head of pipe
  [0] hop — '1' -> Head of Pipe producer Sch , '0' -> No hop
{0x9B8+0x1C*i} DMA{i}_prod0_control (i=0..4) — Controlling producer socket0 for DMA{i}
  [8:1] cons_select — consumer select for DMA{i} prod socket 0. Used in decrementing count of producer buffer
  [0] prod_en — '1' -> Producer socket 0 enable , '0' Disable
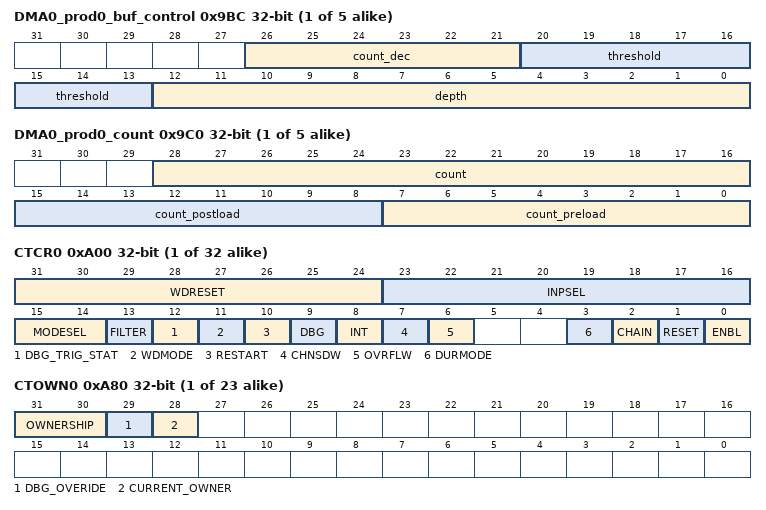
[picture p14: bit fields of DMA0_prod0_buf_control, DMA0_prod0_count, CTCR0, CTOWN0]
{0x9BC+0x1C*i} DMA{i}_prod0_buf_control (i=0..4) — Controlling producer socket0 buffer for DMA{i}
  fields as HWA14_prod0_buf_control
{0x9C0+0x1C*i} DMA{i}_prod0_count access per field (i=0..4) — Defining count values for pre/post load for generating pend by DMA{i} prod0
  fields as HWA14_prod0_count
0x9F0 CTGNBL0 — Counter Timer Global Enable Register 0. This enables Counter 0 to 31
  [7:0] ENABLE — The individual bit is this field enables the corresponding counter. Bits 30 and 31 will be high if global time stamp output interface is enabled
0x9F4 CTGNBL1 — Counter Timer Global Enable Register 1. This enables Counter 32 to 63
  [7:0] ENABLE — The individual bit is this field enables the corresponding counter
0x9F8 CTGRST0 — Counter Timer Global Reset Register 0. This resets Counter 0 to 31
  [7:0] RESET — The individual bit is this field resets the corresponding counter. These bits are self-clearing, once a '1' is written, after the counters are reset these bits are cleared. When Global Time Stamp output interface is enabled, counter 31 and counter 30 should not be written to any value
0x9FC CTGRST1 — Counter Timer Global Reset Register 0. This resets Counter 32 to 63
  [7:0] RESET — The individual bit is this field resets the corresponding counter. These bits are self-clearing, once a '1' is written, after the counters are reset these bits are cleared.
{0xA00+4i} CTCR{i} access per field (i=0..31) — Counter Timer Control Register {i}
  [31:24] WDRESET rw — WD reset event input selector. Only available for modules capable of timer and counter functions. This bit is reserved (read only) for counter registers which are only counter function
  [23:16] INPSEL rw — Counter Timer input selection. For WD mode it is the start event selector
  [15:14] MODESEL rw — Counter is in duration or occurrence mode. Only writable by debug accesses
  [13] FILTER rw — Use associated operating mode filter in CTMODEFILTERn
  [12] DBG_TRIG_STAT rw — Debug event triggered. Write 1 will clear this bit. Only available for modules capable of timer and counter functions. This bit is reserved (read only) for counter registers which are only counter function
  [11] WDMODE rw — WD Timer mode selection. Only available for modules capable of timer and counter functions. This bit is reserved (read only) for counter registers which are only counter function
  [10] RESTART rw — Restart the timer after an interval match. Only available for modules capable of timer and counter functions. This bit is reserved (read only) for counter registers which are only counter function
  [9] DBG rw — Signal debug logic on interval match. Only available for modules capable of timer and counter functions. This bit is reserved (read only) for counter registers which are only counter function
  [8] INT rw — Generate interrupt on interval match. Only available for modules capable of timer and counter functions. This bit is reserved (read only) for counter registers which are only counter function
  [7] CHNSDW rw — Counter has a shadow register for chain reads. Only valid on counters with an even number index
  [6] OVRFLW rw — Counter is in duration or occurrence mode
  [3] DURMODE rw — Counter is in duration or occurrence mode
  [2] CHAIN rw — Counter is chained to an adjacent counter
  [1] RESET rw — Counter reset control
  [0] ENBL rw — Counter enable control
{0xA80+4i} intr_vector_reg_level_vpac_out_{i} ro (i=0..5) — Interrupt Vector for level_vpac_out_{i}
  [31:0] intr_vector_level_vpac_out_{i} — Interrupt Vector
{0xA80+4i} CTOWN{i} access per field (i=0..22) — Counter/Timer Ownership register {i}
  [31:30] OWNERSHIP rw — Counter/Timer Ownership Status. The Read encoding is (0=Available, 1=Claimed, 2=Enabled, 3=Reserved). The write commands are (0=release, 1=claim, 2=enable, 3=nop)
  [29] DBG_OVERIDE rw — This bit indicates the debugger is Claiming the resource, always reads back as 1
  [28] CURRENT_OWNER ro — This value reflects the Counter/Timer ownership when the register is in a non-Available state, 1=Ap owned, 0=Dbg owned
{0x968+0x24*i} DMA{i}_scheduler_control access per field (i=8..10) — Scheduler Control Register
  fields as DMA0_scheduler_control
{0x96C+0x24*i} DMA{i}_HOP (i=8..10) — Scheduler HOP Control Register. Help in detecting eop within scheduler. Once configured, it counts task/channel starts and stops issuing further starts. Specifically useful for Head of pipe dma scheduler .
  fields as DMA0_HOP
{0xA98+4i} intr_vector_reg_pulse_vpac_out_{i} ro (i=0..5) — Interrupt Vector for pulse_vpac_out_{i}
  [31:0] intr_vector_pulse_vpac_out_{i} — Interrupt Vector
{0x978+0x24*i} DMA{i}_prod0_control (i=8..10) — Controlling producer socket0 for DMA{i}
  fields as DMA0_prod0_control
{0x97C+0x24*i} DMA{i}_prod0_buf_control (i=8..10) — Controlling producer socket0 buffer for DMA{i}
  fields as HWA14_prod0_buf_control
{0x980+0x24*i} DMA{i}_prod0_count access per field (i=8..10) — Defining count values for pre/post load for generating pend by DMA{i} prod0
  fields as HWA14_prod0_count
{0x984+0x24*i} DMA{i}_pa0_control (i=8..10) — control register to manage pattern adapter on DMA{i} prod socket0
  fields as HWA14_pa0_control
{0x988+0x24*i} DMA{i}_pa0_prodcount access per field (i=8..10) — count values for HWA{i} prod socket0
  fields as HWA14_pa0_prodcount
0xADC CTOWN23 access per field — Counter/Timer Ownership register2 3
  fields as CTOWN0
{0xA80+4i} CTOWN{i} access per field (i=24..31) — Counter/Timer Ownership register {i}
  fields as CTOWN0
{0xB00+4i} CTFILT{i} access per field (i=0..31) — Counter Timer {i} Filter Register. These filters are only activated if the CTCRn : FILTER is set
  [7] SECSUPER rw — Counter functions while system is in Secure-Supervisor mode
  [6] SECUSER rw — Counter functions while system is in Secure-User mode
  [5] RSUPER rw — Counter functions while system is in Root-Supervisor node
  [4] RUSER rw — Counter functions while system is in Root-User mode
  [3] NRSUPER rw — Counter functions while system is in Non-Root-Supervisor mode
  [2] NRUSER rw — Counter functions while system is in in Non-Root-User mode
  [1] IDLE rw — Counter functions while system/core is in idle
  [0] FREE rw — Counter functions while system/core is halted
{0xB80+4i} CTCNTR{i} ro (i=0..31) — Counter Timer Counter Register {i}
  [31:0] COUNT — This field reflects the current value of the counter. It is incremented when the system events configured in the corresponding Counter Control Register is asserted. If CTCRn.CHNSHD is set, the Counter will increment when the low order counter rolls over.
0xC00 CT_EOI access per field — Counter Timer EOI Register. This register is the End of Interrupt used by SW to signal HW that an interrupt event service is complete and an interrupt can be rearmed. This register exists only if NUMTIMR > 0
  [0] EOI rw — EOI value
{0xC00+0x20*i} hts_cfg_fw_region_{i}_control (i=0..7) — The FW Region {i} Control Register defines the control fields for the slave hts.s_vbusp region {i} firewall.
  fields as intd_cfg_fw_region_0_control
{0xC00+0x20*i} msram3_fw_region_{i}_control (i=0..7) — The FW Region {i} Control Register defines the control fields for the slave ksbus_msram3.slv region {i} firewall.
  fields as intd_cfg_fw_region_0_control
0xC04 CTIRQSTAT_RAW — Counter Timer IRQSTATUS RAW Register. This register indicates the raw status of the interrupt. It can be written by SW for testing. This register exists only if NUMTIMR > 0
  [31:0] TIM_INTn_IRQ — IRQSTATUS_RAW value. The individual bits is this field correspond to individual interrupts generated for each timer associated with Counter Timer Control Register (CTCRn : INT).
{0xC04+0x20*i} hts_cfg_fw_region_{i}_permission_0 (i=0..7) — The FW Region {i} Permission 0 Register defines the permissions for the slave hts.s_vbusp region {i} firewall.
  fields as intd_cfg_fw_region_0_permission_0
{0xC04+0x20*i} msram3_fw_region_{i}_permission_0 (i=0..7) — The FW Region {i} Permission 0 Register defines the permissions for the slave ksbus_msram3.slv region {i} firewall.
  fields as intd_cfg_fw_region_0_permission_0
0xC08 CTIRQSTAT — Counter Timer IRQSTATUS Register. This bit clears the interrupt event. SW can also read this bit to indicate that the interrupt is active and enabled. This register exists only if NUMTIMR > 0
  [31:0] TIM_INTn_IE — IRQSTATUS value. The individual bits is this field correspond to individual interrupts generated for each timer associated with Counter Timer Control Register (CTCRn : INT).
{0xC08+0x20*i} hts_cfg_fw_region_{i}_permission_1 (i=0..7) — The FW Region {i} Permission 1 Register defines the permissions for the slave hts.s_vbusp region {i} firewall.
  fields as intd_cfg_fw_region_0_permission_0
{0xC08+0x20*i} msram3_fw_region_{i}_permission_1 (i=0..7) — The FW Region {i} Permission 1 Register defines the permissions for the slave ksbus_msram3.slv region {i} firewall.
  fields as intd_cfg_fw_region_0_permission_0
0xC0C CTIRQENABLE_SET — Counter Timer IRQENABLE_SET Register. This register is to enable generation of Interrupt Event used by SW. This register exists only if NUMTIMR > 0
  [31:0] TIM_INTn_IES — IRQSET value. This bit sets the enable of the interrupt event. SW can also read this bit to determine if the interrupt is enabled. The individual bits is this field correspond to individual interrupts generated for each timer associated with Counter Timer Control Register (CTCRn : INT).
{0xC0C+0x20*i} hts_cfg_fw_region_{i}_permission_2 (i=0..7) — The FW Region {i} Permission 2 Register defines the permissions for the slave hts.s_vbusp region {i} firewall.
  fields as intd_cfg_fw_region_0_permission_0
{0xC0C+0x20*i} msram3_fw_region_{i}_permission_2 (i=0..7) — The FW Region {i} Permission 2 Register defines the permissions for the slave ksbus_msram3.slv region {i} firewall.
  fields as intd_cfg_fw_region_0_permission_0
0xC10 CTIRQENABLE_CLR — Counter Timer IRQENABLE_CLR Register. This register is to disable generation of Interrupt Event used by SW. This register exists only if NUMTIMR > 0
  [31:0] TIM_INTn_IEC — IRQCLR value. This bit clears the enable of the interrupt event. SW can also read this bit to determine if the interrupt is enabled. The individual bits is this field correspond to individual interrupts generated for each timer associated with Counter Timer Control Register (CTCRn : INT).
{0xC10+0x20*i} hts_cfg_fw_region_{i}_start_address_l access per field (i=0..7) — The FW Region {i} Start Address Low Register defines the start address bits 31 to 0 for the slave hts.s_vbusp region {i} firewall.
  fields as intd_cfg_fw_region_0_start_address_l
{0xC10+0x20*i} msram3_fw_region_{i}_start_address_l access per field (i=0..7) — The FW Region {i} Start Address Low Register defines the start address bits 31 to 0 for the slave ksbus_msram3.slv region {i} firewall.
  fields as intd_cfg_fw_region_0_start_address_l
{0xC14+0x20*i} hts_cfg_fw_region_{i}_start_address_h (i=0..7) — The FW Region {i} Start Address High Register defines the start address bits 47 to 32 for the slave hts.s_vbusp region {i} firewall.
  [15:0] start_address_h — Start address bits 47 to 32.
{0xC14+0x20*i} msram3_fw_region_{i}_start_address_h (i=0..7) — The FW Region {i} Start Address High Register defines the start address bits 47 to 32 for the slave ksbus_msram3.slv region {i} firewall.
  [15:0] start_address_h — Start address bits 47 to 32.
{0xC18+0x20*i} hts_cfg_fw_region_{i}_end_address_l access per field (i=0..7) — The FW Region {i} End Address Low Register defines the end address bits 31 to 0 to include for the slave hts.s_vbusp region {i} firewall.
  fields as intd_cfg_fw_region_0_end_address_l
{0xC18+0x20*i} msram3_fw_region_{i}_end_address_l access per field (i=0..7) — The FW Region {i} End Address Low Register defines the end address bits 31 to 0 to include for the slave ksbus_msram3.slv region {i} firewall.
  fields as intd_cfg_fw_region_0_end_address_l
{0xC1C+0x20*i} hts_cfg_fw_region_{i}_end_address_h (i=0..7) — The FW Region {i} End Address High Register defines the end address bits 47 to 32 to include for the slave hts.s_vbusp region {i} firewall.
  fields as intd_cfg_fw_region_0_end_address_h
